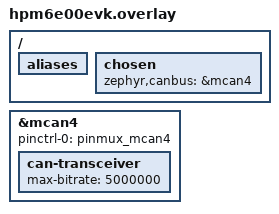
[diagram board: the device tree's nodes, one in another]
/*
 * Copyright 2025 HPMicro
 * SPDX-License-Identifier: Apache-2.0
 */

/ {
	aliases {
	};
	chosen {
        zephyr,canbus = &mcan4;
	};

};
&mcan4 {
    status = "okay";
    pinctrl-0 = <&pinmux_mcan4>;
    pinctrl-names = "default";
    	can-transceiver {
		max-bitrate = <5000000>;
	};
};
